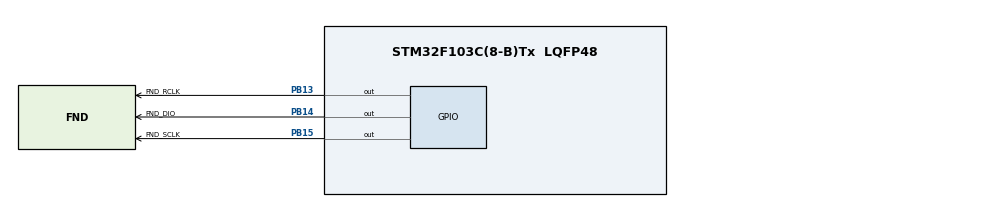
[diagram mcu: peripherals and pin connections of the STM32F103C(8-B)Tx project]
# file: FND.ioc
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Mcu.Family=STM32F1
Mcu.Name=STM32F103C(8-B)Tx
Mcu.Package=LQFP48
NVIC.PriorityGroup=NVIC_PRIORITYGROUP_4
PB13.GPIO_Label=FND_RCLK
PB13.GPIO_ModeDefaultOutputPP=GPIO_MODE_OUTPUT_PP
PB13.GPIO_PuPd=GPIO_PULLUP
PB13.GPIO_Speed=GPIO_SPEED_FREQ_HIGH
PB13.PinState=GPIO_PIN_SET
PB13.Signal=GPIO_Output
PB14.GPIO_Label=FND_DIO
PB14.GPIO_ModeDefaultOutputPP=GPIO_MODE_OUTPUT_PP
PB14.GPIO_PuPd=GPIO_PULLUP
PB14.GPIO_Speed=GPIO_SPEED_FREQ_HIGH
PB14.PinState=GPIO_PIN_SET
PB14.Signal=GPIO_Output
PB15.GPIO_Label=FND_SCLK
PB15.GPIO_ModeDefaultOutputPP=GPIO_MODE_OUTPUT_PP
PB15.GPIO_PuPd=GPIO_PULLUP
PB15.GPIO_Speed=GPIO_SPEED_FREQ_HIGH
PB15.PinState=GPIO_PIN_SET
PB15.Signal=GPIO_Output
ProjectManager.HeapSize=0x200
ProjectManager.StackSize=0x400
ProjectManager.TargetToolchain=STM32CubeIDE
RCC.APB1Freq_Value=8000000
RCC.APB2Freq_Value=8000000
board=custom

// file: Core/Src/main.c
/* USER CODE BEGIN Header */
/**
  ******************************************************************************
  * @file           : main.c
  * @brief          : Main program body
  ******************************************************************************
  * @attention
  *
  * Copyright (c) 2024 STMicroelectronics.
  * All rights reserved.
  *
  * This software is licensed under terms that can be found in the LICENSE file
  * in the root directory of this software component.
  * If no LICENSE file comes with this software, it is provided AS-IS.
  *
  ******************************************************************************
  */
/* USER CODE END Header */
#include "main.h"

void SystemClock_Config(void);
static void MX_GPIO_Init(void);
/* USER CODE BEGIN PFP */
void send(uint8_t data);
void send_port (uint8_t data, uint8_t port);

/* USER CODE END PFP */

int main(void)
{

  /* MCU Configuration--------------------------------------------------------*/

  /* Reset of all peripherals, Initializes the Flash interface and the Systick. */
  HAL_Init();

  /* Configure the system clock */
  SystemClock_Config();

  /* Initialize all configured peripherals */
  MX_GPIO_Init();

  /* Infinite loop */
  /* USER CODE BEGIN WHILE */
  while (1)
  {

	  send_port(0b11111110, 0b0001);

	  HAL_Delay(1000);

    /* USER CODE END WHILE */

  }
}

void SystemClock_Config(void)
{
  RCC_OscInitTypeDef RCC_OscInitStruct = {0};
  RCC_ClkInitTypeDef RCC_ClkInitStruct = {0};

  /** Initializes the RCC Oscillators according to the specified parameters
  * in the RCC_OscInitTypeDef structure.
  */
  RCC_OscInitStruct.OscillatorType = RCC_OSCILLATORTYPE_HSI;
  RCC_OscInitStruct.HSIState = RCC_HSI_ON;
  RCC_OscInitStruct.HSICalibrationValue = RCC_HSICALIBRATION_DEFAULT;
  RCC_OscInitStruct.PLL.PLLState = RCC_PLL_NONE;
  if (HAL_RCC_OscConfig(&RCC_OscInitStruct) != HAL_OK)
  {
    Error_Handler();
  }

  /** Initializes the CPU, AHB and APB buses clocks
  */
  RCC_ClkInitStruct.ClockType = RCC_CLOCKTYPE_HCLK|RCC_CLOCKTYPE_SYSCLK
                              |RCC_CLOCKTYPE_PCLK1|RCC_CLOCKTYPE_PCLK2;
  RCC_ClkInitStruct.SYSCLKSource = RCC_SYSCLKSOURCE_HSI;
  RCC_ClkInitStruct.AHBCLKDivider = RCC_SYSCLK_DIV1;
  RCC_ClkInitStruct.APB1CLKDivider = RCC_HCLK_DIV1;
  RCC_ClkInitStruct.APB2CLKDivider = RCC_HCLK_DIV1;

  if (HAL_RCC_ClockConfig(&RCC_ClkInitStruct, FLASH_LATENCY_0) != HAL_OK)
  {
    Error_Handler();
  }
}

static void MX_GPIO_Init(void)
{
  GPIO_InitTypeDef GPIO_InitStruct = {0};

  /* GPIO Ports Clock Enable */
  __HAL_RCC_GPIOB_CLK_ENABLE();

  /*Configure GPIO pin Output Level */
  HAL_GPIO_WritePin(GPIOB, FND_RCLK_Pin|FND_DIO_Pin|FND_SCLK_Pin, GPIO_PIN_SET);

  /*Configure GPIO pins : FND_RCLK_Pin FND_DIO_Pin FND_SCLK_Pin */
  GPIO_InitStruct.Pin = FND_RCLK_Pin|FND_DIO_Pin|FND_SCLK_Pin;
  GPIO_InitStruct.Mode = GPIO_MODE_OUTPUT_PP;
  GPIO_InitStruct.Pull = GPIO_PULLUP;
  GPIO_InitStruct.Speed = GPIO_SPEED_FREQ_HIGH;
  HAL_GPIO_Init(GPIOB, &GPIO_InitStruct);

}

/* USER CODE BEGIN 4 */

void send(uint8_t data)
{
	for (uint8_t i = 0; i < 8; i++)
	{
		if (data & 0x80) HAL_GPIO_WritePin(FND_DIO_GPIO_Port, FND_DIO_Pin, SET);
		else HAL_GPIO_WritePin(FND_DIO_GPIO_Port, FND_DIO_Pin, RESET);

		data <<= 1;

		HAL_GPIO_WritePin(FND_SCLK_GPIO_Port, FND_SCLK_Pin, SET);
		HAL_GPIO_WritePin(FND_SCLK_GPIO_Port, FND_SCLK_Pin, RESET);
	}
}

void send_port (uint8_t data, uint8_t port)
{
	send(data);
	send(port);
	HAL_GPIO_WritePin(FND_RCLK_GPIO_Port, FND_RCLK_Pin, RESET);
	HAL_GPIO_WritePin(FND_RCLK_GPIO_Port, FND_RCLK_Pin, SET);
}

/* USER CODE END 4 */

void Error_Handler(void)
{
  __disable_irq();
  while (1)
  {
  }
}
